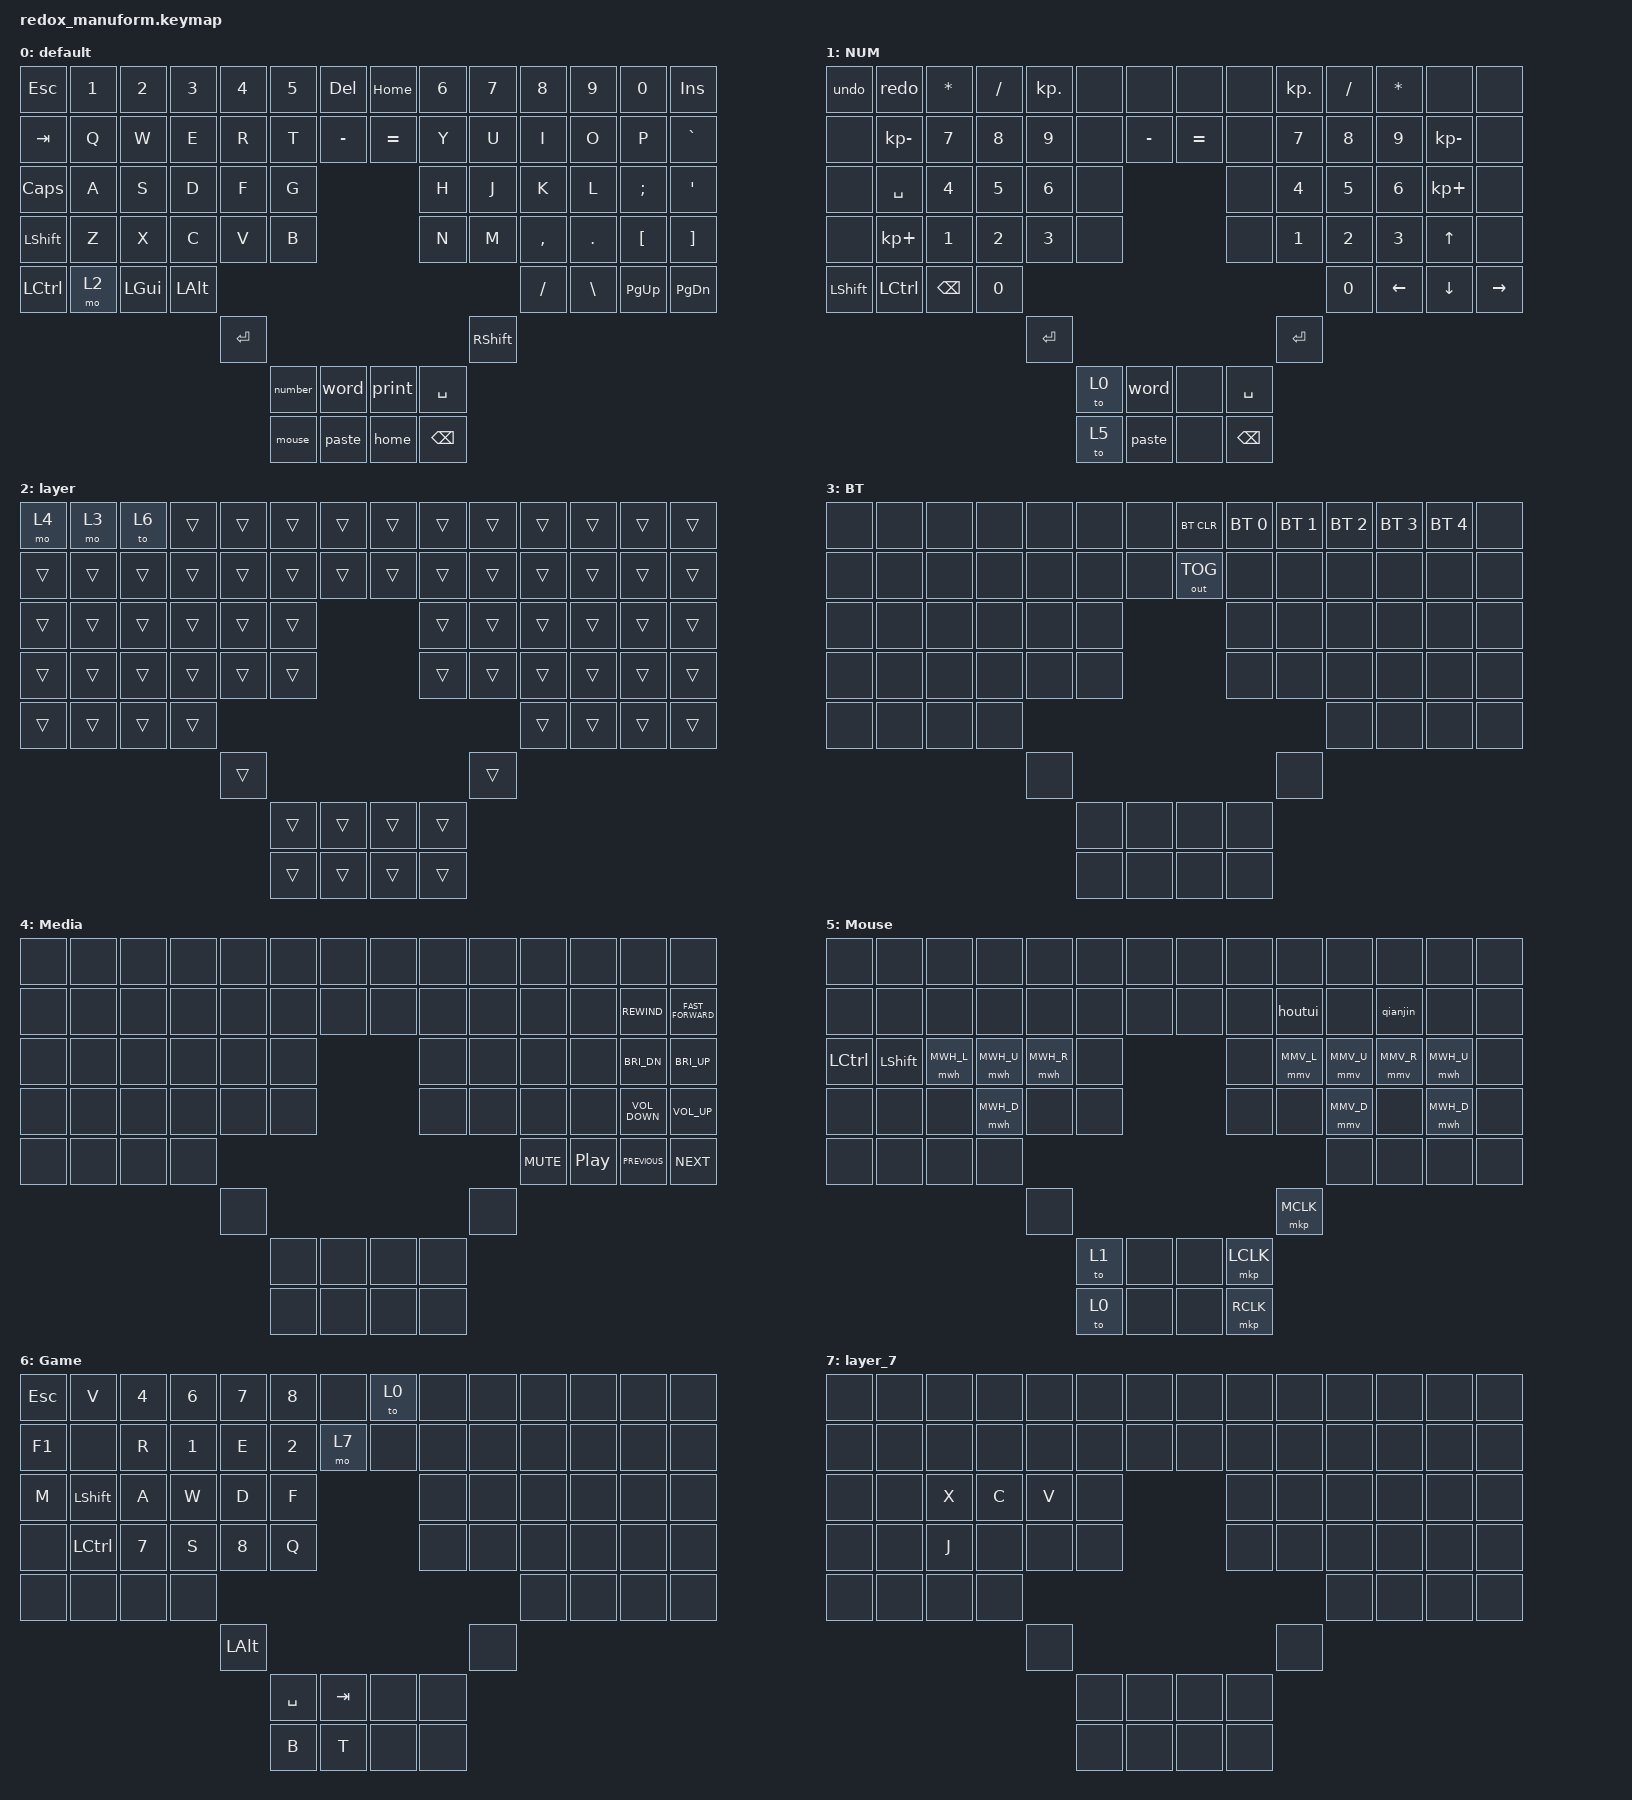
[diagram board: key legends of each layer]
#include <dt-bindings/zmk/mouse.h>
#include <behaviors.dtsi>
#include <dt-bindings/zmk/bt.h>
#include <dt-bindings/zmk/keys.h>
#include <dt-bindings/zmk/outputs.h>

// mouse move settings

#define MMV_U MOVE_VERT(-650)
#define MMV_D MOVE_VERT(650)
#define MMV_L MOVE_HOR(-650)
#define MMV_R MOVE_HOR(650)

&mmv {
    time-to-max-speed-ms = <600>;
    acceleration-exponent = <1>;
    delay-ms = <0>;
};

// mouse wheel settings

#define MWH_U SCROLL_VERT(9)
#define MWH_D SCROLL_VERT(-9)
#define MWH_L SCROLL_HOR(-9)
#define MWH_R SCROLL_HOR(9)

&mwh {
    time-to-max-speed-ms = <2000>;
    acceleration-exponent = <0>;
    delay-ms = <0>;
};

/ {
    macros {
        copy: copy {
            label = "fuzhi";
            compatible = "zmk,behavior-macro";
            #binding-cells = <0>;
            bindings =
                <&macro_press>,
                <&kp LCTRL>,
                <&macro_tap>,
                <&kp C>,
                <&macro_release>,
                <&kp LCTRL>;
        };
        cut: cut {
            compatible = "zmk,behavior-macro";
            label = "jianqie";
            #binding-cells = <0>;
            bindings =
                <&macro_press>,
                <&kp LCTRL>,
                <&macro_tap>,
                <&kp X>,
                <&macro_release>,
                <&kp LCTRL>;
        };
        paste: paste {
            compatible = "zmk,behavior-macro";
            label = "zhantie";
            #binding-cells = <0>;
            bindings =
                <&macro_press>,
                <&kp LCTRL>,
                <&macro_tap>,
                <&kp V>,
                <&macro_release>,
                <&kp LCTRL>;
        };
        all: all {
            compatible = "zmk,behavior-macro";
            label = "quanxuan";
            #binding-cells = <0>;
            bindings =
                <&macro_press>,
                <&kp LCTRL>,
                <&macro_tap>,
                <&kp A>,
                <&macro_release>,
                <&kp LCTRL>;
        };
        home: home {
            compatible = "zmk,behavior-macro";
            label = "zhuomian";
            #binding-cells = <0>;
            bindings =
                <&macro_press>,
                <&kp LEFT_GUI>,
                <&macro_tap>,
                <&kp D>,
                <&macro_release>,
                <&kp LEFT_GUI>;
        };
        print: print {
            compatible = "zmk,behavior-macro";
            label = "jietu";
            #binding-cells = <0>;
            bindings =
                <&macro_press>,
                <&kp LEFT_GUI &kp LSHFT>,
                <&macro_tap>,
                <&kp S>,
                <&macro_release>,
                <&kp LEFT_GUI &kp LSHFT>;
        };
        undo: undo {
            compatible = "zmk,behavior-macro";
            label = "UNDO";
            #binding-cells = <0>;
            bindings =
                <&macro_press>,
                <&kp LCTRL>,
                <&macro_tap>,
                <&kp Z>,
                <&macro_release>,
                <&kp LCTRL>;
        };
        redo: redo {
            compatible = "zmk,behavior-macro";
            label = "REDO";
            #binding-cells = <0>;
            bindings =
                <&macro_press>,
                <&kp LCTRL>,
                <&macro_tap>,
                <&kp Y>,
                <&macro_release>,
                <&kp LCTRL>;
        };
        qianjin: qianjin {
            compatible = "zmk,behavior-macro";
            label = "QIANJIN";
            #binding-cells = <0>;
            bindings =
                <&macro_press>,
                <&kp LEFT_ALT>,
                <&macro_tap>,
                <&kp RIGHT>,
                <&macro_release>,
                <&kp LEFT_ALT>;
        };
        houtui: houtui {
            compatible = "zmk,behavior-macro";
            label = "HOUTUI";
            #binding-cells = <0>;
            bindings =
                <&macro_press>,
                <&kp LEFT_ALT>,
                <&macro_tap>,
                <&kp LEFT>,
                <&macro_release>,
                <&kp LEFT_ALT>;
        };
    };

    behaviors {
        word: word {
            compatible = "zmk,behavior-tap-dance";
            label = "WORD";
            #binding-cells = <0>;
            bindings =
                <&copy>,
                <&cut>,
                <&all>;
        };
        number: number {
            compatible = "zmk,behavior-tap-dance";
            label = "NUMBER";
            #binding-cells = <0>;
            bindings =
                <&mo 1>,
                <&none>,
                <&to 1>;
        };
        mouse: mouse {
            compatible = "zmk,behavior-tap-dance";
            label = "MOUSE";
            #binding-cells = <0>;
            bindings =
                <&mo 5>,
                <&to 5>;
        };
    };

    keymap {
        compatible = "zmk,keymap";

        default {
            // --------------------------------------------------------------------------------------------------------------------------------
            // | ESC   |  1  |  2  |   3   |  4  |  5  |   (   |           ---           |  )    |  6  |  7  |  8    |  9   | 0  |    BKSP   |
            // | TAB   |  Q  |  W  |   E   |  R  |  T  |   [   |           ---           |  ]    |  Y  |  U  |  I    |  O   | P  |     -     |
            // | CTRL  |  A  |  S  |   D   |  F  |  G  |                   ---                   |  H  |  J  |  K    |  L   | ;  |     '     |
            // | SHIFT |  Z  |  X  |   C   |  V  |  B  |                   ---                   |  N  |  M  |  ,    |  .   | /  | SHFT(RET) |
            // | CRTL  | ALT | GUI | LOWER |                               ---                               | LEFT  | DOWN | UP |   RIGHT   |
            //                             |    GUI    |                   ---                   |   RAISE   |
            //                             |   PG_up   | SPACE |           ---           |  HOME |   SPACE   |   
            //                             |   PG_DOWN | LOWER |           ---           |  DEL  |   END     |

            bindings = <
  &kp ESC  &kp N1    &kp N2    &kp N3     &kp N4   &kp N5    &kp DEL   &kp HOME     &kp N6     &kp N7     &kp N8    &kp N9     &kp N0    &kp INS
  &kp TAB   &kp Q     &kp W     &kp E      &kp R    &kp T  &kp MINUS  &kp EQUAL      &kp Y      &kp U      &kp I     &kp O      &kp P  &kp GRAVE
 &kp CAPS   &kp A     &kp S     &kp D      &kp F    &kp G                            &kp H      &kp J      &kp K     &kp L   &kp SEMI    &kp SQT
&kp LSHFT   &kp Z     &kp X     &kp C      &kp V    &kp B                            &kp N      &kp M  &kp COMMA   &kp DOT   &kp LBKT   &kp RBKT
&kp LCTRL   &mo 2  &kp LGUI  &kp LALT                                                                   &kp FSLH  &kp BSLH  &kp PG_UP  &kp PG_DN
                                       &kp ENTER                                            &kp RSHFT
                                                  &number      &word     &print  &kp SPACE
                                                   &mouse     &paste      &home   &kp BSPC
            >;
        };

        NUM {
            bindings = <
         &undo         &redo  &kp STAR  &kp FSLH  &kp KP_DOT  &none      &none      &none      &none  &kp KP_DOT  &kp FSLH  &kp STAR         &none      &none
         &none  &kp KP_MINUS    &kp N7    &kp N8      &kp N9  &none  &kp MINUS  &kp EQUAL      &none      &kp N7    &kp N8    &kp N9  &kp KP_MINUS      &none
         &none     &kp SPACE    &kp N4    &kp N5      &kp N6  &none                            &none      &kp N4    &kp N5    &kp N6   &kp KP_PLUS      &none
         &none   &kp KP_PLUS    &kp N1    &kp N2      &kp N3  &none                            &none      &kp N1    &kp N2    &kp N3        &kp UP      &none
&kp LEFT_SHIFT     &kp LCTRL  &kp BSPC    &kp N0                                                                    &kp N0  &kp LEFT      &kp DOWN  &kp RIGHT
                                                     &kp RET                                             &kp RET
                                                              &to 0      &word      &none  &kp SPACE
                                                              &to 5     &paste      &none   &kp BSPC
            >;

            label = "NUM";
        };

        layer {
            bindings = <
 &mo 4   &mo 3   &to 6  &trans  &trans  &trans  &trans  &trans  &trans  &trans  &trans  &trans  &trans  &trans
&trans  &trans  &trans  &trans  &trans  &trans  &trans  &trans  &trans  &trans  &trans  &trans  &trans  &trans
&trans  &trans  &trans  &trans  &trans  &trans                  &trans  &trans  &trans  &trans  &trans  &trans
&trans  &trans  &trans  &trans  &trans  &trans                  &trans  &trans  &trans  &trans  &trans  &trans
&trans  &trans  &trans  &trans                                                  &trans  &trans  &trans  &trans
                                &trans                                  &trans
                                        &trans  &trans  &trans  &trans
                                        &trans  &trans  &trans  &trans
            >;

            label = "layer";
        };

        BT {
            bindings = <
&none  &none  &none  &none  &none  &none  &none    &bt BT_CLR  &bt BT_SEL 0  &bt BT_SEL 1  &bt BT_SEL 2  &bt BT_SEL 3  &bt BT_SEL 4  &none
&none  &none  &none  &none  &none  &none  &none  &out OUT_TOG         &none         &none         &none         &none         &none  &none
&none  &none  &none  &none  &none  &none                              &none         &none         &none         &none         &none  &none
&none  &none  &none  &none  &none  &none                              &none         &none         &none         &none         &none  &none
&none  &none  &none  &none                                                                        &none         &none         &none  &none
                            &none                                                   &none
                                   &none  &none         &none         &none
                                   &none  &none         &none         &none
            >;
        };

        Media {
            bindings = <
&none  &none  &none  &none  &none  &none  &none  &none  &none  &none       &none             &none              &none               &none
&none  &none  &none  &none  &none  &none  &none  &none  &none  &none       &none             &none       &kp C_REWIND  &kp C_FAST_FORWARD
&none  &none  &none  &none  &none  &none                &none  &none       &none             &none       &kp C_BRI_DN        &kp C_BRI_UP
&none  &none  &none  &none  &none  &none                &none  &none       &none             &none  &kp C_VOLUME_DOWN        &kp C_VOL_UP
&none  &none  &none  &none                                            &kp C_MUTE  &kp C_PLAY_PAUSE     &kp C_PREVIOUS          &kp C_NEXT
                            &none                              &none
                                   &none  &none  &none  &none
                                   &none  &none  &none  &none
            >;

            label = "Media";
        };

        Mouse {
            bindings = <
    &none      &none       &none       &none       &none  &none  &none  &none      &none       &none       &none       &none       &none  &none
    &none      &none       &none       &none       &none  &none  &none  &none      &none     &houtui       &none    &qianjin       &none  &none
&kp LCTRL  &kp LSHFT  &mwh MWH_L  &mwh MWH_U  &mwh MWH_R  &none                    &none  &mmv MMV_L  &mmv MMV_U  &mmv MMV_R  &mwh MWH_U  &none
    &none      &none       &none  &mwh MWH_D       &none  &none                    &none       &none  &mmv MMV_D       &none  &mwh MWH_D  &none
    &none      &none       &none       &none                                                               &none       &none       &none  &none
                                                   &none                                   &mkp MCLK
                                                          &to 1  &none  &none  &mkp LCLK
                                                          &to 0  &none  &none  &mkp RCLK
            >;

            label = "Mouse";
        };

        Game {
            bindings = <
&kp ESC      &kp V  &kp N4  &kp N6        &kp N7     &kp N8    &none  &to 0  &none  &none  &none  &none  &none  &none
 &kp F1      &none   &kp R  &kp N1         &kp E     &kp N2    &mo 7  &none  &none  &none  &none  &none  &none  &none
  &kp M  &kp LSHFT   &kp A   &kp W         &kp D      &kp F                  &none  &none  &none  &none  &none  &none
  &none  &kp LCTRL  &kp N7   &kp S        &kp N8      &kp Q                  &none  &none  &none  &none  &none  &none
  &none      &none   &none   &none                                                         &none  &none  &none  &none
                                    &kp LEFT_ALT                                    &none
                                                  &kp SPACE  &kp TAB  &none  &none
                                                      &kp B    &kp T  &none  &none
            >;

            label = "Game";
        };

        layer_7 {
            bindings = <
&none  &none  &none  &none  &none  &none  &none  &none  &none  &none  &none  &none  &none  &none
&none  &none  &none  &none  &none  &none  &none  &none  &none  &none  &none  &none  &none  &none
&none  &none  &kp X  &kp C  &kp V  &none                &none  &none  &none  &none  &none  &none
&none  &none  &kp J  &none  &none  &none                &none  &none  &none  &none  &none  &none
&none  &none  &none  &none                                            &none  &none  &none  &none
                            &none                              &none
                                   &none  &none  &none  &none
                                   &none  &none  &none  &none
            >;
        };
    };
};
